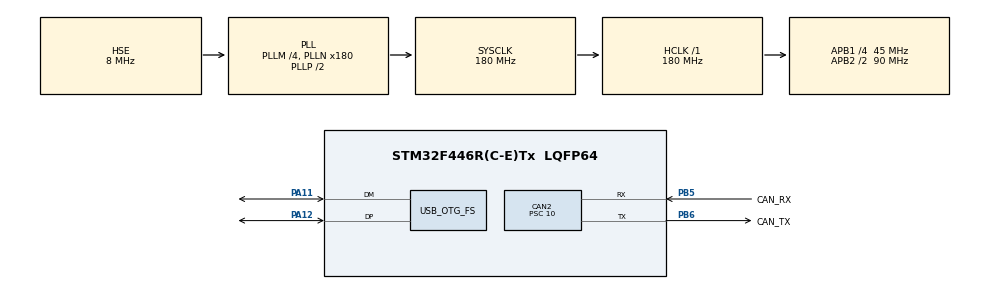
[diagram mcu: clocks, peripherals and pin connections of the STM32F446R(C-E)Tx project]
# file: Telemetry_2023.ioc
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CAN2.BS1=CAN_BS1_15TQ
CAN2.BS2=CAN_BS2_2TQ
CAN2.CalculateBaudRate=250000
CAN2.CalculateTimeBit=4000
CAN2.CalculateTimeQuantum=222.22222222222223
CAN2.Prescaler=10
Mcu.Family=STM32F4
Mcu.Name=STM32F446R(C-E)Tx
Mcu.Package=LQFP64
NVIC.CAN2_RX0_IRQn=true\:0\:0\:false\:false\:true\:true\:true\:true
NVIC.OTG_FS_IRQn=true\:0\:0\:false\:false\:true\:false\:true\:true
NVIC.PriorityGroup=NVIC_PRIORITYGROUP_4
PA11.Mode=Device_Only
PA11.Signal=USB_OTG_FS_DM
PA12.Mode=Device_Only
PA12.Signal=USB_OTG_FS_DP
PB5.GPIO_Label=CAN_RX
PB5.Mode=CAN_Activate
PB5.Signal=CAN2_RX
PB6.GPIO_Label=CAN_TX
PB6.Mode=CAN_Activate
PB6.Signal=CAN2_TX
PC14-OSC32_IN.Mode=LSE-External-Oscillator
PC14-OSC32_IN.Signal=RCC_OSC32_IN
PC15-OSC32_OUT.Mode=LSE-External-Oscillator
PC15-OSC32_OUT.Signal=RCC_OSC32_OUT
PH0-OSC_IN.Mode=HSE-External-Oscillator
PH0-OSC_IN.Signal=RCC_OSC_IN
PH1-OSC_OUT.Mode=HSE-External-Oscillator
PH1-OSC_OUT.Signal=RCC_OSC_OUT
ProjectManager.HeapSize=0x200
ProjectManager.StackSize=0x400
ProjectManager.TargetToolchain=STM32CubeIDE
RCC.AHBFreq_Value=180000000
RCC.APB1CLKDivider=RCC_HCLK_DIV4
RCC.APB1Freq_Value=45000000
RCC.APB1TimFreq_Value=90000000
RCC.APB2CLKDivider=RCC_HCLK_DIV2
RCC.APB2Freq_Value=90000000
RCC.APB2TimFreq_Value=180000000
RCC.CortexFreq_Value=180000000
RCC.HCLKFreq_Value=180000000
RCC.HSE_VALUE=8000000
RCC.PLLM=4
RCC.PLLN=180
RCC.PLLQ=7
RCC.PLLSAIM=4
RCC.PLLSAIN=96
RCC.PLLSAIP=RCC_PLLSAIP_DIV4
RCC.SYSCLKFreq_VALUE=180000000
RCC.SYSCLKSource=RCC_SYSCLKSOURCE_PLLCLK
RCC.USBCLockSelection=RCC_CLK48CLKSOURCE_PLLSAIP
RCC.USBFreq_Value=48000000
RCC.VCOOutputFreq_Value=360000000
USB_DEVICE.CLASS_NAME_FS=CDC
USB_DEVICE.PRODUCT_STRING_CDC_FS=TELEMETRY_USB
USB_DEVICE.VirtualMode-CDC_FS=Cdc
USB_DEVICE.VirtualModeFS=Cdc_FS
USB_OTG_FS.VirtualMode=Device_Only
VP_USB_DEVICE_VS_USB_DEVICE_CDC_FS.Mode=CDC_FS
board=custom

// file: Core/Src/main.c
/* USER CODE BEGIN Header */
/**
  ******************************************************************************
  * @file           : main.c
  * @brief          : Main program body
  ******************************************************************************
  * @attention
  *
  * Copyright (c) 2022 STMicroelectronics.
  * All rights reserved.
  *
  * This software is licensed under terms that can be found in the LICENSE file
  * in the root directory of this software component.
  * If no LICENSE file comes with this software, it is provided AS-IS.
  *
  ******************************************************************************
  */
/* USER CODE END Header */
#include "main.h"
#include "can.h"
#include "usb_device.h"
#include "gpio.h"

/* USER CODE BEGIN Includes */
#include "usbd_cdc_if.h"
#include "string.h"
#include "stdio.h"
/* USER CODE END Includes */

void SystemClock_Config(void);

int main(void)
{
  /* USER CODE BEGIN 1 */
	//PA12 DATA+, PA11 DATA-
  /* USER CODE END 1 */

  /* MCU Configuration--------------------------------------------------------*/

  /* Reset of all peripherals, Initializes the Flash interface and the Systick. */
  HAL_Init();

  /* Configure the system clock */
  SystemClock_Config();

  /* Initialize all configured peripherals */
  MX_GPIO_Init();
  MX_USB_DEVICE_Init();
  MX_CAN2_Init();
  /* USER CODE BEGIN 2 */
  CAN_setFilter();
  HAL_CAN_Start(&hcan2);
  /* USER CODE END 2 */

  /* Infinite loop */
  while (1)
  {

    /* USER CODE BEGIN 3 */
	sendCAN();
	//CDC_Transmit_FS((uint8_t *)data, strlen(data));
	//HAL_Delay(1000);

	//while(CDC_Transmit_FS((uint8_t *)data, strlen(data))!=USBD_OK);
	//HAL_Delay(50);

	if(HAL_CAN_GetRxFifoFillLevel(&hcan2, CAN_RX_FIFO0) != 0){
		  CAN_RxHeaderTypeDef RxMessage_header;
		  uint8_t Rx_Data[8] = {0,0,0,0,0,0,0,0};

		  HAL_CAN_GetRxMessage(&hcan2, CAN_RX_FIFO0, &RxMessage_header, Rx_Data);

		  char msg[50];

		  sprintf(msg, "@:%ld:%d:%d:%d:%d:%d:%d:%d:%d:%d:|", RxMessage_header.StdId, (uint8_t)RxMessage_header.DLC, Rx_Data[0], Rx_Data[1], Rx_Data[2], Rx_Data[3], Rx_Data[4], Rx_Data[5], Rx_Data[6], Rx_Data[7]);

		  while(CDC_Transmit_FS((uint8_t *)msg, strlen(msg)) != USBD_OK);

	  }
  }
  /* USER CODE END 3 */
}

void SystemClock_Config(void)
{
  RCC_OscInitTypeDef RCC_OscInitStruct = {0};
  RCC_ClkInitTypeDef RCC_ClkInitStruct = {0};

  /** Configure the main internal regulator output voltage
  */
  __HAL_RCC_PWR_CLK_ENABLE();
  __HAL_PWR_VOLTAGESCALING_CONFIG(PWR_REGULATOR_VOLTAGE_SCALE1);

  /** Initializes the RCC Oscillators according to the specified parameters
  * in the RCC_OscInitTypeDef structure.
  */
  RCC_OscInitStruct.OscillatorType = RCC_OSCILLATORTYPE_HSE;
  RCC_OscInitStruct.HSEState = RCC_HSE_ON;
  RCC_OscInitStruct.PLL.PLLState = RCC_PLL_ON;
  RCC_OscInitStruct.PLL.PLLSource = RCC_PLLSOURCE_HSE;
  RCC_OscInitStruct.PLL.PLLM = 4;
  RCC_OscInitStruct.PLL.PLLN = 180;
  RCC_OscInitStruct.PLL.PLLP = RCC_PLLP_DIV2;
  RCC_OscInitStruct.PLL.PLLQ = 7;
  RCC_OscInitStruct.PLL.PLLR = 2;
  if (HAL_RCC_OscConfig(&RCC_OscInitStruct) != HAL_OK)
  {
    Error_Handler();
  }

  /** Activate the Over-Drive mode
  */
  if (HAL_PWREx_EnableOverDrive() != HAL_OK)
  {
    Error_Handler();
  }

  /** Initializes the CPU, AHB and APB buses clocks
  */
  RCC_ClkInitStruct.ClockType = RCC_CLOCKTYPE_HCLK|RCC_CLOCKTYPE_SYSCLK
                              |RCC_CLOCKTYPE_PCLK1|RCC_CLOCKTYPE_PCLK2;
  RCC_ClkInitStruct.SYSCLKSource = RCC_SYSCLKSOURCE_PLLCLK;
  RCC_ClkInitStruct.AHBCLKDivider = RCC_SYSCLK_DIV1;
  RCC_ClkInitStruct.APB1CLKDivider = RCC_HCLK_DIV4;
  RCC_ClkInitStruct.APB2CLKDivider = RCC_HCLK_DIV2;

  if (HAL_RCC_ClockConfig(&RCC_ClkInitStruct, FLASH_LATENCY_5) != HAL_OK)
  {
    Error_Handler();
  }
}

void Error_Handler(void)
{
  __disable_irq();
  while (1)
  {
  }
}
